# MS32F031 register map
File version: 1.0
CPU: CM0 r1p0, little endian, no MPU, no FPU, 3 interrupt priority bits
Registers are 32-bit, read-write, reset 0x0 unless marked. A register's access mark holds for its fields unless they carry their own. Offsets are from the block's base; [hi:lo] are bit positions; {n}, {i} and the like mark numbered series.

## Flash
Base 0x40022000
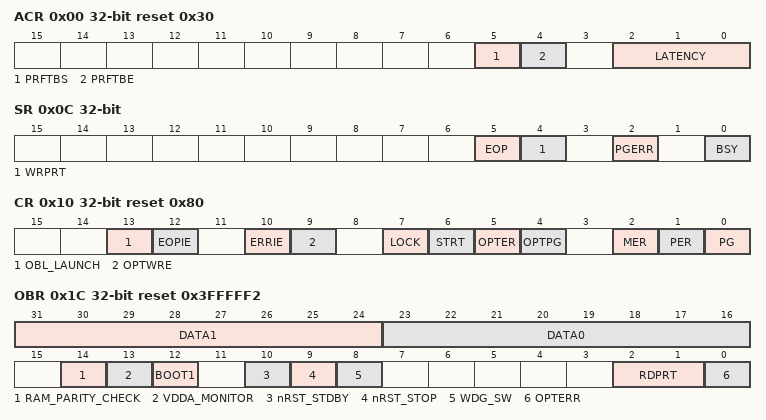
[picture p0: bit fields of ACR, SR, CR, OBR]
0x00 ACR access per field reset 0x30 — Flash access control register
  [5] PRFTBS ro — Prefetch buffer status
  [4] PRFTBE rw — Prefetch buffer enable
  [2:0] LATENCY rw
0x04 KEYR wo — Flash key register
  [31:0] FKEY — Flash Key
0x08 OPTKEYR wo — Flash option key register
  [31:0] OPTKEY — Option byte key
0x0C SR access per field — Flash status register
  [5] EOP rw — End of operation
  [4] WRPRT rw — Write protection error
  [2] PGERR rw — Programming error
  [0] BSY ro — Busy
0x10 CR reset 0x80 — Flash control register
  [13] OBL_LAUNCH — Force option byte loading
  [12] EOPIE — End of operation interrupt enable
  [10] ERRIE — Error interrupt enable
  [9] OPTWRE — Option bytes write enable
  [7] LOCK
  [6] STRT — Start
  [5] OPTER — Option byte erase
  [4] OPTPG — Option byte programming
  [2] MER — Mass erase
  [1] PER — Page erase
  [0] PG — Programming
0x14 AR wo — Flash address register
  [31:0] FAR — Flash address
0x1C OBR ro reset 0x3FFFFF2 — Option byte register
  [31:24] DATA1
  [23:16] DATA0
  [14] RAM_PARITY_CHECK
  [13] VDDA_MONITOR
  [12] BOOT1
  [10] nRST_STDBY
  [9] nRST_STOP
  [8] WDG_SW
  [2:1] RDPRT — Read protection level status
  [0] OPTERR — Option byte error
0x20 WRPR ro reset 0xFFFFFFFF — Write protection register
  [15:0] WRP — Write protect

## DBGMCU — Debug support
Base 0x40015800
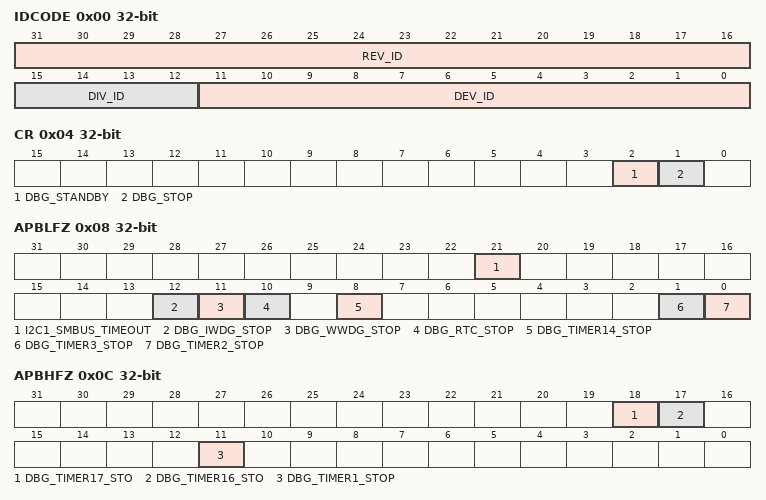
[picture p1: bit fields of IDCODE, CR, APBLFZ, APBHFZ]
0x00 IDCODE ro — MCU Device ID Code Register
  [31:16] REV_ID — Revision Identifier
  [15:12] DIV_ID — Division Identifier
  [11:0] DEV_ID — Device Identifier
0x04 CR — Debug MCU Configuration Register
  [2] DBG_STANDBY — Debug Standby Mode
  [1] DBG_STOP — Debug Stop Mode
0x08 APBLFZ — APB Low Freeze Register
  [21] I2C1_SMBUS_TIMEOUT — SMBUS timeout mode stopped when Core is halted
  [12] DBG_IWDG_STOP — Debug Independent Wachdog stopped when Core is halted
  [11] DBG_WWDG_STOP — Debug Window Wachdog stopped when Core is halted
  [10] DBG_RTC_STOP — Debug RTC stopped when Core is halted
  [8] DBG_TIMER14_STOP — Debug Timer 14 stopped when Core is halted
  [1] DBG_TIMER3_STOP — Debug Timer 3 stopped when Core is halted
  [0] DBG_TIMER2_STOP — Debug Timer 2 stopped when Core is halted
0x0C APBHFZ — APB High Freeze Register
  [18] DBG_TIMER17_STO — Debug Timer 17 stopped when Core is halted
  [17] DBG_TIMER16_STO — Debug Timer 16 stopped when Core is halted
  [11] DBG_TIMER1_STOP — Debug Timer 1 stopped when Core is halted

## COMP_OPAMP — Voltage comparator and Operational amplifier
Base 0x40013C00
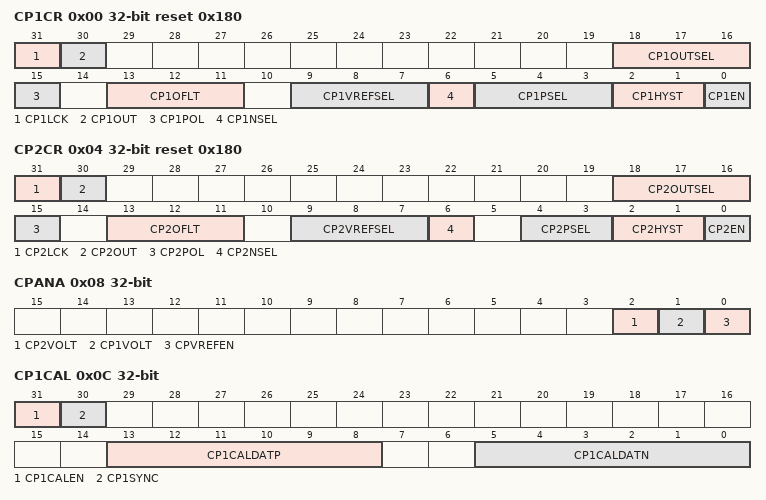
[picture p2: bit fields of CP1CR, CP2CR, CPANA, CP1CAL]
0x00 CP1CR access per field reset 0x180 — Comparator 1 Control Register
  [31] CP1LCK rw — Comparator 1 lock key
  [30] CP1OUT ro — Comparator 1 output
  [18:16] CP1OUTSEL rw — Comparator 1 output function selection
  [15] CP1POL rw — Comparator 1 output polarity selection
  [13:11] CP1OFLT rw — Comparator 1 output filter period
  [9:7] CP1VREFSEL rw — Comparator 1 vref voltage selection
  [6] CP1NSEL rw — Comparator 1 negative input selection
  [5:3] CP1PSEL rw — Comparator 1 positive input selection
  [2:1] CP1HYST rw — Comparator 1 hysteresis selection
  [0] CP1EN rw — Comparator 1 enable
0x04 CP2CR access per field reset 0x180 — Comparator 2 Control Register
  [31] CP2LCK rw — Comparator 2 lock key
  [30] CP2OUT ro — Comparator 2 output
  [18:16] CP2OUTSEL rw — Comparator 2 output function selection
  [15] CP2POL rw — Comparator 2 output polarity selection
  [13:11] CP2OFLT rw — Comparator 2 output filter period
  [9:7] CP2VREFSEL rw — Comparator 2 vref voltage selection
  [6] CP2NSEL rw — Comparator 2 negative input selection
  [4:3] CP2PSEL rw — Comparator 2 negative input selection
  [2:1] CP2HYST rw — Comparator 2 hysteresis selection
  [0] CP2EN rw — Comparator 2 enable
0x08 CPANA — Comparator Analog Register
  [2] CP2VOLT — Comparator 2 vref voltage source selection
  [1] CP1VOLT — Comparator 1 vref voltage source selection
  [0] CPVREFEN — Comparator vref voltage enable
0x0C CP1CAL access per field — Comparator 1 calibration Register
  [31] CP1CALEN rw — Comparator 1 calibration enable
  [30] CP1SYNC ro — Comparator 1 the synchronization of calibration
  [13:8] CP1CALDATP rw — Comparator 1 the data of positive calibration
  [5:0] CP1CALDATN rw — Comparator 1 the data of negative calibration
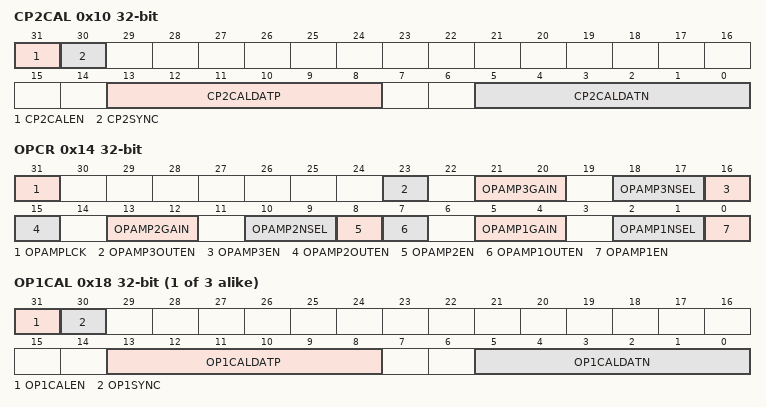
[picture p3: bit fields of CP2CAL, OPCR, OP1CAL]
0x10 CP2CAL access per field — Comparator 2 calibration Register
  [31] CP2CALEN rw — Comparator 2 calibration enable
  [30] CP2SYNC ro — Comparator 2 the synchronization of calibration
  [13:8] CP2CALDATP rw — Comparator 2 the data of positive calibration
  [5:0] CP2CALDATN rw — Comparator 2 the data of negative calibration
0x14 OPCR — Operational Amplifier Control Register
  [31] OPAMPLCK — Operational Amplifier lock key
  [23] OPAMP3OUTEN — Operational Amplifier 3 output enable
  [21:20] OPAMP3GAIN — Operational Amplifier 3 output gain selection
  [18:17] OPAMP3NSEL — Operational Amplifier 3 negative input selection
  [16] OPAMP3EN — Operational Amplifier 3 enable
  [15] OPAMP2OUTEN — Operational Amplifier 2 output enable
  [13:12] OPAMP2GAIN — Operational Amplifier 2 output gain selection
  [10:9] OPAMP2NSEL — Operational Amplifier 2 negative input selection
  [8] OPAMP2EN — Operational Amplifier 2 enable
  [7] OPAMP1OUTEN — Operational Amplifier 1 output enable
  [5:4] OPAMP1GAIN — Operational Amplifier 1 output gain selection
  [2:1] OPAMP1NSEL — Operational Amplifier 1 negative input selection
  [0] OPAMP1EN — Operational Amplifier 1 enable
{0x14+4i} OP{i}CAL access per field (i=1..3) — Operational Amplifier {i} calibration Register
  [31] OP{i}CALEN rw — Operational Amplifier {i} calibration enable
  [30] OP{i}SYNC ro — Operational Amplifier {i} the synchronization of calibration
  [13:8] OP{i}CALDATP rw — Operational Amplifier {i} the data of positive calibration
  [5:0] OP{i}CALDATN rw — Operational Amplifier {i} the data of negative calibration
